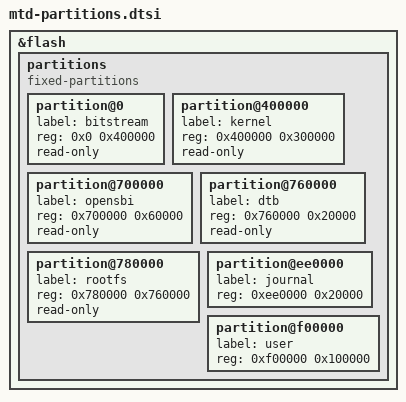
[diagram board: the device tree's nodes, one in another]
// SPDX-License-Identifier: (GPL-2.0 OR MIT)
/*
 * GENERATED by sw/dts/gen_mtd_partitions.py from FLASHBOOT_LAYOUT +
 * FLASHBOOT_RESERVED in sw/litex/milan_soc.py.  DO NOT EDIT BY HAND -
 * regenerate, and let `gen_mtd_partitions.py --check` prove the two agree.
 *
 * Attaches to the flash node LiteX's json2dts emits for LiteSPI:
 *
 *     litespiflash: spiflash@<csr> {
 *         compatible = "litex,spiflash";
 *         flash: flash@0 { compatible = "jedec,spi-nor"; reg = <0 SIZE>; };
 *     };
 *
 * so the `&flash` label below is the one that base tree already defines.
 * Append this fragment to the generated base.dts before dtc, exactly like
 * the kl,dma-ether overlay (see sw/dts/README.md).
 *
 * NOT YET PROVEN ON A BOARD: no deployed tree carries an mtd node today and
 * no mtd driver is known to bind to this controller in this kernel config.
 * docs/design/SAVED_STATE_FASTCONNECT.md section 11 gate G1 is the falsifier
 * (`cat /proc/mtd` after a flash + boot).
 */

&flash {
	#address-cells = <1>;
	#size-cells = <1>;

	partitions {
		compatible = "fixed-partitions";
		#address-cells = <1>;
		#size-cells = <1>;

		/* boot image: 4096 KiB */
		partition@0 {
			label = "bitstream";
			reg = <0x0 0x400000>;
			read-only;
		};
		/* boot image: 3072 KiB */
		partition@400000 {
			label = "kernel";
			reg = <0x400000 0x300000>;
			read-only;
		};
		/* boot image: 384 KiB */
		partition@700000 {
			label = "opensbi";
			reg = <0x700000 0x60000>;
			read-only;
		};
		/* boot image: 128 KiB */
		partition@760000 {
			label = "dtb";
			reg = <0x760000 0x20000>;
			read-only;
		};
		/* boot image: 7552 KiB */
		partition@780000 {
			label = "rootfs";
			reg = <0x780000 0x760000>;
			read-only;
		};
		/* WRITABLE: 128 KiB */
		partition@ee0000 {
			label = "journal";
			reg = <0xee0000 0x20000>;
		};
		/* WRITABLE: 1024 KiB */
		partition@f00000 {
			label = "user";
			reg = <0xf00000 0x100000>;
		};
	};
};

/* 7 partitions, 0x1000000 of 0x1000000 bytes allocated, erase block 0x10000 */
